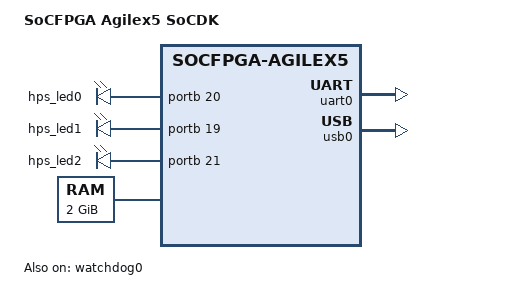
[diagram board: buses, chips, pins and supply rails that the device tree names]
// SPDX-License-Identifier: GPL-2.0-only
/*
 * Copyright (C) 2023, Intel Corporation
 */
#include "socfpga_agilex5.dtsi"

/ {
	model = "SoCFPGA Agilex5 SoCDK";
	compatible = "intel,socfpga-agilex5-socdk", "intel,socfpga-agilex5";

	aliases {
		serial0 = &uart0;
	};

	chosen {
		stdout-path = "serial0:115200n8";
	};

	leds {
		compatible = "gpio-leds";
		led-0 {
			label = "hps_led0";
			gpios = <&portb 20 GPIO_ACTIVE_HIGH>;
		};

		led-1 {
			label = "hps_led1";
			gpios = <&portb 19 GPIO_ACTIVE_HIGH>;
		};

		led-2 {
			label = "hps_led2";
			gpios = <&portb 21 GPIO_ACTIVE_HIGH>;
		};
	};

	memory {
		device_type = "memory";
		reg = <0x0 0x80000000 0x0 0x80000000>;
	};
};

&gpio1 {
	status = "okay";
};

&osc1 {
	clock-frequency = <25000000>;
};

&uart0 {
	status = "okay";
};

&usb0 {
	status = "okay";
	disable-over-current;
};

&watchdog0 {
	status = "okay";
};
